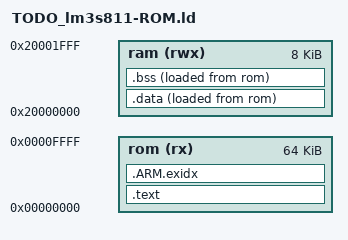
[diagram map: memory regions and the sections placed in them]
OUTPUT_FORMAT("elf32-littlearm", "elf32-bigarm",
	      "elf32-littlearm")
GROUP(-lc -lgcc)
OUTPUT_ARCH(arm)
ENTRY(ResetISR)
SEARCH_DIR(.)
__DYNAMIC  =  0;

MEMORY
{
  rom (rx) : ORIGIN = 0, LENGTH = 64k
  ram (rwx) : ORIGIN = 0x20000000, LENGTH = 8k
}

SECTIONS
{
  .text :
  {
    CREATE_OBJECT_SYMBOLS
    *(.isr_vector .isr_vector.*)
    *(.text .text.* .gnu.linkonce.t.*)
    *(.plt)
    *(.gnu.warning)
    *(.glue_7t) *(.glue_7)

    . = ALIGN(0x4);
    /* These are for running static constructors and destructors under ELF.  */
    KEEP (*crtbegin.o(.ctors))
    KEEP (*(EXCLUDE_FILE (*crtend.o) .ctors))
    KEEP (*(SORT(.ctors.*)))
    KEEP (*crtend.o(.ctors))
    KEEP (*crtbegin.o(.dtors))
    KEEP (*(EXCLUDE_FILE (*crtend.o) .dtors))
    KEEP (*(SORT(.dtors.*)))
    KEEP (*crtend.o(.dtors))

    *(.rodata .rodata.* .gnu.linkonce.r.*)

    *(.ARM.extab* .gnu.linkonce.armextab.*)
    *(.gcc_except_table) 
    *(.eh_frame_hdr)
    *(.eh_frame)

    *(.init)
    *(.fini)

    PROVIDE_HIDDEN (__preinit_array_start = .);
    KEEP (*(.preinit_array))
    PROVIDE_HIDDEN (__preinit_array_end = .);
    PROVIDE_HIDDEN (__init_array_start = .);
    KEEP (*(SORT(.init_array.*)))
    KEEP (*(.init_array))
    PROVIDE_HIDDEN (__init_array_end = .);
    PROVIDE_HIDDEN (__fini_array_start = .);
    KEEP (*(.fini_array))
    KEEP (*(SORT(.fini_array.*)))
    PROVIDE_HIDDEN (__fini_array_end = .);
  } >rom
  /* .ARM.exidx is sorted, so has to go in its own output section.  */
   __exidx_start = .;
  .ARM.exidx :
  {
    *(.ARM.exidx* .gnu.linkonce.armexidx.*)
  } >rom
  __exidx_end = .;
  _etext = .;

  .data :
  {
    __data_load = LOADADDR (.data);
    __data_start = .;
    _data = .;
    *(vtable vtable.*)
    KEEP(*(.jcr))
    *(.got.plt) *(.got)
    *(.shdata)
    *(.data .data.* .gnu.linkonce.d.*)
    . = ALIGN (4);
    _edata = .;
  } >ram AT>rom

  .bss :
  {
    __bss_start__ = . ;
    _bss = .;
    *(.shbss)
    *(.bss .bss.* .gnu.linkonce.b.*)
    *(COMMON)
    . = ALIGN (8);
    __bss_end__ = .;
    _ebss = .;
    . = ALIGN(8);
    _end = .;
    __end = _end;
    PROVIDE(end = .);
  } >ram AT>rom
  

  __top_stack__ = ORIGIN(RAM)+LENGTH(RAM);
  PROVIDE(__TOP_STACK = __top_stack__);


  .stab 0 (NOLOAD) :
  {
    *(.stab)
  }

  .stabstr 0 (NOLOAD) :
  {
    *(.stabstr)
  }
  /* DWARF debug sections.
     Symbols in the DWARF debugging sections are relative to the beginning
     of the section so we begin them at 0.  */
  /* DWARF 1 */
  .debug          0 : { *(.debug) }
  .line           0 : { *(.line) }
  /* GNU DWARF 1 extensions */
  .debug_srcinfo  0 : { *(.debug_srcinfo) }
  .debug_sfnames  0 : { *(.debug_sfnames) }
  /* DWARF 1.1 and DWARF 2 */
  .debug_aranges  0 : { *(.debug_aranges) }
  .debug_pubnames 0 : { *(.debug_pubnames) }
  /* DWARF 2 */
  .debug_info     0 : { *(.debug_info .gnu.linkonce.wi.*) }
  .debug_abbrev   0 : { *(.debug_abbrev) }
  .debug_line     0 : { *(.debug_line) }
  .debug_frame    0 : { *(.debug_frame) }
  .debug_str      0 : { *(.debug_str) }
  .debug_loc      0 : { *(.debug_loc) }
  .debug_macinfo  0 : { *(.debug_macinfo) }
  /* SGI/MIPS DWARF 2 extensions */
  .debug_weaknames 0 : { *(.debug_weaknames) }
  .debug_funcnames 0 : { *(.debug_funcnames) }
  .debug_typenames 0 : { *(.debug_typenames) }
  .debug_varnames  0 : { *(.debug_varnames) }
  .note.gnu.arm.ident 0 : { KEEP (*(.note.gnu.arm.ident)) }
  .ARM.attributes 0 : { KEEP (*(.ARM.attributes)) }
  /DISCARD/ : { *(.note.GNU-stack)  }
}


MEMORY
{
    FLASH (rx) : ORIGIN = 0x00000000, LENGTH = 0x10000
    SRAM (rwx) : ORIGIN = 0x20000000, LENGTH = 0x2000
}

/* Section Definitions */
SECTIONS
{
   .text :
  {
	KEEP(*(.isr_vector .isr_vector.*))
	*(.text .text.*)
	*(.gnu.linkonce.t.*)
	*(.glue_7)
	*(.glue_7t)
	*(.gcc_except_table)
	*(.rodata .rodata*)
	*(.gnu.linkonce.r.*)
	_etext = .;
  } > FLASH
   
  .data : AT (_etext)
  {
	_data = .;
	*(vtable vtable.*)
	*(.data .data.*)
	*(.gnu.linkonce.d*)
	. = ALIGN(4);
	_edata = . ;
  } > SRAM
 
  /* .bss section which is used for uninitialized data */
  .bss (NOLOAD) :
  {
    _bss = . ;
    *(.bss .bss.*)
    *(.gnu.linkonce.b*)
    *(COMMON)
	. = ALIGN(4);
	_ebss = . ;
  } > SRAM
  
  .stackarea (NOLOAD) :
  {
    . = ALIGN(8);
	*(.stackarea .stackarea.*)
	. = ALIGN(8);
  } > SRAM
  
  . = ALIGN(4);
  _end = . ;
  PROVIDE (end = .);

  /* Stabs debugging sections.  */
  .stab          0 : { *(.stab) }
  .stabstr       0 : { *(.stabstr) }
  .stab.excl     0 : { *(.stab.excl) }
  .stab.exclstr  0 : { *(.stab.exclstr) }
  .stab.index    0 : { *(.stab.index) }
  .stab.indexstr 0 : { *(.stab.indexstr) }
  .comment       0 : { *(.comment) }
  /* DWARF debug sections.
     Symbols in the DWARF debugging sections are relative to the beginning
     of the section so we begin them at 0.  */
  /* DWARF 1 */
  .debug          0 : { *(.debug) }
  .line           0 : { *(.line) }
  /* GNU DWARF 1 extensions */
  .debug_srcinfo  0 : { *(.debug_srcinfo) }
  .debug_sfnames  0 : { *(.debug_sfnames) }
  /* DWARF 1.1 and DWARF 2 */
  .debug_aranges  0 : { *(.debug_aranges) }
  .debug_pubnames 0 : { *(.debug_pubnames) }
  /* DWARF 2 */
  .debug_info     0 : { *(.debug_info .gnu.linkonce.wi.*) }
  .debug_abbrev   0 : { *(.debug_abbrev) }
  .debug_line     0 : { *(.debug_line) }
  .debug_frame    0 : { *(.debug_frame) }
  .debug_str      0 : { *(.debug_str) }
  .debug_loc      0 : { *(.debug_loc) }
  .debug_macinfo  0 : { *(.debug_macinfo) }
  /* SGI/MIPS DWARF 2 extensions */
  .debug_weaknames 0 : { *(.debug_weaknames) }
  .debug_funcnames 0 : { *(.debug_funcnames) }
  .debug_typenames 0 : { *(.debug_typenames) }
  .debug_varnames  0 : { *(.debug_varnames) }
}
